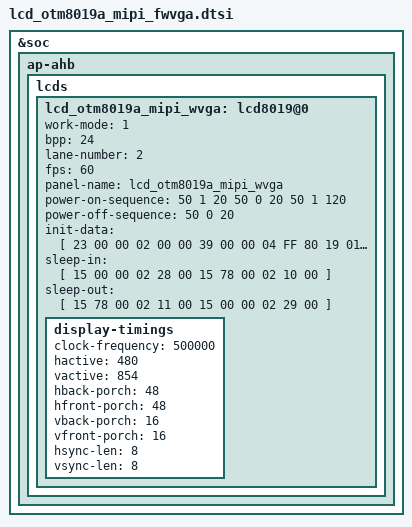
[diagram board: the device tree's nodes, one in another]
&soc { ap-ahb { lcds {
		lcd_otm8019a_mipi_wvga: lcd8019@0 {

			work-mode = <1>;
			bpp = <24>;
			lane-number = <2>;

			fps = <60>;
			panel-name = "lcd_otm8019a_mipi_wvga";

			power-on-sequence = <
						50  1  20
						50  0  20
						50  1  120
						>;
			power-off-sequence = <
						50  0  20
						>;

			init-data = [
				23 00 00 02 00 00
				39 00 00 04 FF 80 19 01
				23 00 00 02 00 80
				39 00 00 03 FF 80 19
				23 00 00 02 00 03
				23 00 00 02 FF 01
				23 00 00 02 00 00
				39 00 00 03 D8 6F 6F
				23 00 00 02 00 82
				23 00 00 02 C5 B0
				23 00 00 02 00 A1
				23 00 00 02 C1 08
				23 00 00 02 00 A3
				23 00 00 02 C0 1B
				23 00 00 02 00 B4
				23 00 00 02 C0 77
				23 00 00 02 00 81
				23 00 00 02 C4 83
				23 00 00 02 00 90
				39 00 00 04 C5 4E A7 01
				23 00 00 02 00 B1
				23 00 00 02 C5 A9
				23 00 00 02 00 00
				23 00 00 02 D9 17
				23 00 00 02 00 00
				39 00 00 15 E1 00 10 22 38 50 62 67 92 7f 94 75 65 7e 6c 72 6c 65 5d 53 02
				23 00 00 02 00 00
				39 00 00 15 E2 00 10 22 38 50 62 67 92 7f 94 75 65 7e 6c 72 6c 65 5d 53 02
				23 00 00 02 00 00
				39 00 00 15 E1 00 02 07 12 22 37 41 78 6b 85 7f 6b 82 6b 71 69 61 58 4c 00
				23 00 00 02 00 00
				39 00 00 15 E2 00 02 07 12 22 37 41 78 6b 85 7f 6b 82 6b 71 69 61 58 4c 00
				23 00 00 02 00 A7
				23 00 00 02 B3 00
				23 00 00 02 00 92
				23 00 00 02 B3 45
				23 00 00 02 00 90
				23 00 00 02 B3 02
				23 00 00 02 00 00
				23 00 00 02 36 00
				23 00 00 02 00 90
				39 00 00 07 C0 00 15 00 00 00 03
				23 00 00 02 00 A0
				23 00 00 02 C1 E8
				23 00 00 02 00 A6
				39 00 00 04 C1 01 00 00
				23 00 00 02 00 80
				39 00 00 07 CE 87 05 14 86 05 14
				23 00 00 02 00 90
				39 00 00 07 CE 33 54 14 33 55 14
				23 00 00 02 00 A0
				39 00 00 0f CE 38 03 03 58 00 14 00 38 02 03 59 00 14 00
				23 00 00 02 00 B0
				39 00 00 0f CE 38 01 03 5A 00 14 00 38 00 03 5B 00 14 00
				23 00 00 02 00 C0
				39 00 00 0f CE 30 00 03 5C 00 14 00 30 01 03 5D 00 14 00
				23 00 00 02 00 D0
				39 00 00 0f CE 38 05 03 5E 00 14 00 38 04 03 5F 00 14 00
				23 00 00 02 00 C0
				39 00 00 0b CF 00 00 00 00 00 00 01 00 00 00
				23 00 00 02 00 C0
				39 00 00 10 CB 00 01 01 01 01 00 00 01 01 01 01 00 00 00 00
				23 00 00 02 00 D0
				39 00 00 10 CB 00 00 00 00 00 00 00 00 00 00 01 01 01 01 00
				23 00 00 02 00 E0
				39 00 00 0b CB 00 01 01 01 01 00 00 00 00 00
				23 00 00 02 00 80
				39 00 00 0b CC 00 26 25 02 06 00 00 0A 0E 0C
				23 00 00 02 00 90
				39 00 00 10 CC 10 00 00 00 00 00 00 00 00 00 00 00 00 00 00
				23 00 00 02 00 A0
				39 00 00 10 CC 0f 0b 0d 09 00 00 05 01 25 26 00 00 00 00 00
				23 00 00 02 00 B0
				39 00 00 0b CC 00 25 26 05 01 00 00 0D 09 0B
				23 00 00 02 00 C0
				39 00 00 10 CC 0F 00 00 00 00 00 00 00 00 00 00 00 00 00 00
				23 00 00 02 00 D0
				39 00 00 10 CC 10 0c 0a 0e 00 00 02 06 26 25 00 00 00 00 00
				23 00 00 02 00 98
				23 00 00 02 C0 00
				23 00 00 02 00 A9
				23 00 00 02 C0 06
				23 00 00 02 00 B0
				39 00 00 04 C1 20 00 00
				23 00 00 02 00 E1
				39 00 00 03 C0 40 18
				23 00 00 02 00 80
				23 00 00 02 C4 30
				23 00 00 02 00 80
				39 00 00 03 C1 03 33
				23 00 00 02 00 90
				23 0a 00 02 B6 B4
				23 00 00 02 00 94
				23 00 00 02 C5 66
				23 00 00 02 00 00
				23 00 00 04 FF FF FF FF
				23 78 00 02 11 00
				23 30 00 02 29 00
				];
			sleep-in =  [
				15 00 00 02 28 00
				15 78 00 02 10 00
				];
			sleep-out = [
				15 78 00 02 11 00
				15 00 00 02 29 00
				];

			display-timings {
				clock-frequency = <500000>;
				hactive = <480>;
				vactive = <854>;
				hback-porch = <48>;
				hfront-porch = <48>;
				vback-porch = <16>;
				vfront-porch = <16>;
				hsync-len = <8>;
				vsync-len = <8>;
			};
		};
}; }; };
